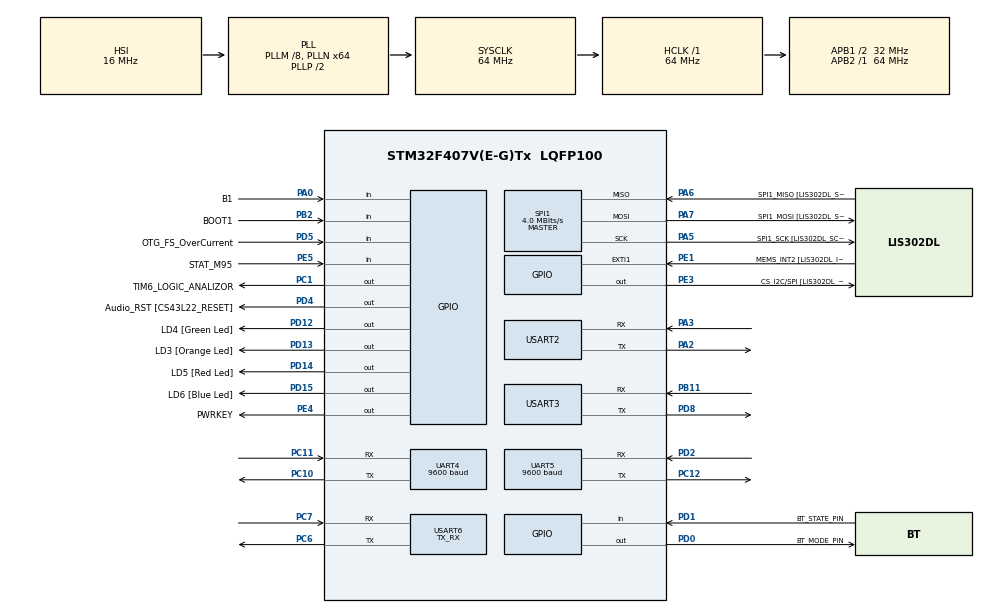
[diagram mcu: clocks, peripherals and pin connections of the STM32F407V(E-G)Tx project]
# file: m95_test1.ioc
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Mcu.Family=STM32F4
Mcu.Name=STM32F407V(E-G)Tx
Mcu.Package=LQFP100
NVIC.PriorityGroup=NVIC_PRIORITYGROUP_4
NVIC.SPI1_IRQn=true\:0\:0\:false\:false\:true\:true\:true\:true
NVIC.TIM6_DAC_IRQn=true\:0\:0\:false\:false\:true\:true\:true\:true
NVIC.UART4_IRQn=true\:0\:0\:false\:false\:true\:true\:true\:true
NVIC.UART5_IRQn=true\:0\:0\:false\:false\:true\:true\:true\:true
NVIC.USART2_IRQn=true\:0\:0\:false\:false\:true\:true\:true\:true
NVIC.USART3_IRQn=true\:0\:0\:false\:false\:true\:true\:true\:true
NVIC.USART6_IRQn=true\:0\:0\:false\:false\:true\:true\:true\:true
PA0-WKUP.GPIO_Label=B1
PA0-WKUP.Signal=GPIO_Input
PA13.Mode=Serial_Wire
PA13.Signal=SYS_JTMS-SWDIO
PA14.Mode=Serial_Wire
PA14.Signal=SYS_JTCK-SWCLK
PA2.GPIO_PuPd=GPIO_PULLUP
PA2.Mode=Asynchronous
PA2.Signal=USART2_TX
PA3.GPIO_PuPd=GPIO_PULLUP
PA3.Mode=Asynchronous
PA3.Signal=USART2_RX
PA5.GPIO_Label=SPI1_SCK [LIS302DL_SCL/SPC]
PA5.GPIO_Mode=GPIO_MODE_AF_PP
PA5.GPIO_PuPd=GPIO_NOPULL
PA5.GPIO_Speed=GPIO_SPEED_FREQ_LOW
PA5.Mode=Full_Duplex_Master
PA5.Signal=SPI1_SCK
PA6.GPIO_Label=SPI1_MISO [LIS302DL_SDO]
PA6.GPIO_Mode=GPIO_MODE_AF_PP
PA6.GPIO_PuPd=GPIO_NOPULL
PA6.GPIO_Speed=GPIO_SPEED_FREQ_LOW
PA6.Mode=Full_Duplex_Master
PA6.Signal=SPI1_MISO
PA7.GPIO_Label=SPI1_MOSI [LIS302DL_SDA/SDI/SDO]
PA7.GPIO_Mode=GPIO_MODE_AF_PP
PA7.GPIO_PuPd=GPIO_NOPULL
PA7.GPIO_Speed=GPIO_SPEED_FREQ_LOW
PA7.Mode=Full_Duplex_Master
PA7.Signal=SPI1_MOSI
PB11.GPIO_PuPd=GPIO_PULLUP
PB11.Mode=Asynchronous
PB11.Signal=USART3_RX
PB2.GPIO_Label=BOOT1
PB2.GPIO_Mode=GPIO_MODE_INPUT
PB2.GPIO_PuPd=GPIO_NOPULL
PB2.Signal=GPIO_Input
PB3.GPIO_Label=SWO
PB3.Signal=SYS_JTDO-SWO
PC1.GPIO_Label=TIM6_LOGIC_ANALIZOR
PC1.Signal=GPIO_Output
PC10.GPIO_PuPd=GPIO_PULLUP
PC10.Mode=Asynchronous
PC10.Signal=UART4_TX
PC11.GPIO_PuPd=GPIO_PULLUP
PC11.Mode=Asynchronous
PC11.Signal=UART4_RX
PC12.GPIO_PuPd=GPIO_PULLUP
PC12.Mode=Asynchronous
PC12.Signal=UART5_TX
PC14-OSC32_IN.GPIO_Label=PC14-OSC32_IN
PC14-OSC32_IN.Signal=RCC_OSC32_IN
PC15-OSC32_OUT.GPIO_Label=PC15-OSC32_OUT
PC15-OSC32_OUT.Signal=RCC_OSC32_OUT
PC6.Mode=Asynchronous
PC6.Signal=USART6_TX
PC7.Mode=Asynchronous
PC7.Signal=USART6_RX
PD0.GPIO_Label=BT_MODE_PIN
PD0.GPIO_PuPd=GPIO_PULLDOWN
PD0.Signal=GPIO_Output
PD1.GPIO_Label=BT_STATE_PIN
PD1.GPIO_PuPd=GPIO_PULLDOWN
PD1.Signal=GPIO_Input
PD12.GPIO_Label=LD4 [Green Led]
PD12.GPIO_PuPd=GPIO_NOPULL
PD12.GPIO_Speed=GPIO_SPEED_FREQ_LOW
PD12.Signal=GPIO_Output
PD13.GPIO_Label=LD3 [Orange Led]
PD13.GPIO_PuPd=GPIO_NOPULL
PD13.GPIO_Speed=GPIO_SPEED_FREQ_LOW
PD13.Signal=GPIO_Output
PD14.GPIO_Label=LD5 [Red Led]
PD14.GPIO_PuPd=GPIO_NOPULL
PD14.GPIO_Speed=GPIO_SPEED_FREQ_LOW
PD14.Signal=GPIO_Output
PD15.GPIO_Label=LD6 [Blue Led]
PD15.GPIO_PuPd=GPIO_NOPULL
PD15.GPIO_Speed=GPIO_SPEED_FREQ_LOW
PD15.Signal=GPIO_Output
PD2.GPIO_PuPd=GPIO_PULLUP
PD2.Mode=Asynchronous
PD2.Signal=UART5_RX
PD4.GPIO_Label=Audio_RST [CS43L22_RESET]
PD4.GPIO_PuPd=GPIO_NOPULL
PD4.GPIO_Speed=GPIO_SPEED_FREQ_LOW
PD4.Signal=GPIO_Output
PD5.GPIO_Label=OTG_FS_OverCurrent
PD5.GPIO_Mode=GPIO_MODE_INPUT
PD5.GPIO_PuPd=GPIO_NOPULL
PD5.Signal=GPIO_Input
PD8.GPIO_ModeDefaultPP=GPIO_MODE_AF_PP
PD8.GPIO_PuPd=GPIO_PULLUP
PD8.Mode=Asynchronous
PD8.Signal=USART3_TX
PE1.GPIO_Label=MEMS_INT2 [LIS302DL_INT2]
PE1.Signal=GPXTI1
PE3.GPIO_Label=CS_I2C/SPI [LIS302DL_CS_I2C/SPI]
PE3.GPIO_PuPd=GPIO_NOPULL
PE3.GPIO_Speed=GPIO_SPEED_FREQ_LOW
PE3.Signal=GPIO_Output
PE4.GPIO_Label=PWRKEY
PE4.Signal=GPIO_Output
PE5.GPIO_Label=STAT_M95
PE5.Signal=GPIO_Input
PH0-OSC_IN.GPIO_Label=PH0-OSC_IN
PH0-OSC_IN.Signal=RCC_OSC_IN
PH1-OSC_OUT.GPIO_Label=PH1-OSC_OUT
PH1-OSC_OUT.Signal=RCC_OSC_OUT
ProjectManager.HeapSize=0x400
ProjectManager.StackSize=0x1200
ProjectManager.TargetToolchain=STM32CubeIDE
RCC.48MHZClocksFreq_Value=18285714.285714287
RCC.AHBFreq_Value=64000000
RCC.APB1CLKDivider=RCC_HCLK_DIV2
RCC.APB1Freq_Value=32000000
RCC.APB1TimFreq_Value=64000000
RCC.APB2Freq_Value=64000000
RCC.APB2TimFreq_Value=64000000
RCC.CortexFreq_Value=64000000
RCC.HCLKFreq_Value=64000000
RCC.HSE_VALUE=8000000
RCC.HSI_VALUE=16000000
RCC.LSE_VALUE=32768
RCC.PLLM=8
RCC.PLLN=64
RCC.PLLQ=7
RCC.SYSCLKFreq_VALUE=64000000
RCC.SYSCLKSource=RCC_SYSCLKSOURCE_PLLCLK
RCC.VCOOutputFreq_Value=128000000
SPI1.BaudRatePrescaler=SPI_BAUDRATEPRESCALER_16
SPI1.CLKPhase=SPI_PHASE_1EDGE
SPI1.CLKPolarity=SPI_POLARITY_LOW
SPI1.CalculateBaudRate=4.0 MBits/s
SPI1.Direction=SPI_DIRECTION_2LINES
SPI1.Mode=SPI_MODE_MASTER
SPI1.VirtualType=VM_MASTER
TIM6.AutoReloadPreload=TIM_AUTORELOAD_PRELOAD_ENABLE
TIM6.Period=3200
TIM6.Prescaler=1
UART4.BaudRate=9600
UART4.VirtualMode=Asynchronous
UART5.BaudRate=9600
UART5.VirtualMode=Asynchronous
USART2.OverSampling=UART_OVERSAMPLING_8
USART2.VirtualMode=VM_ASYNC
USART3.OverSampling=UART_OVERSAMPLING_8
USART3.VirtualMode=VM_ASYNC
USART6.Mode=MODE_TX_RX
USART6.VirtualMode=VM_ASYNC
VP_TIM6_VS_ClockSourceINT.Mode=Enable_Timer
board=STM32F407G-DISC1

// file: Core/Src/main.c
/* USER CODE BEGIN Header */
/**
 ******************************************************************************
 * @file           : main.c
 * @brief          : Main program body
 ******************************************************************************
 * @attention
 *
 * Copyright (c) 2023 STMicroelectronics.
 * All rights reserved.
 *
 * This software is licensed under terms that can be found in the LICENSE file
 * in the root directory of this software component.
 * If no LICENSE file comes with this software, it is provided AS-IS.
 *
 ******************************************************************************
 */
/* USER CODE END Header */
#include "main.h"

/* USER CODE BEGIN Includes */
#include "vehicleTrackingSystem.h"
/* USER CODE END Includes */

SPI_HandleTypeDef hspi1;

TIM_HandleTypeDef htim6;

UART_HandleTypeDef huart4;
UART_HandleTypeDef huart5;
UART_HandleTypeDef huart2;
UART_HandleTypeDef huart3;
UART_HandleTypeDef huart6;

void SystemClock_Config(void);
static void MX_GPIO_Init(void);
static void MX_USART2_UART_Init(void);
static void MX_USART3_UART_Init(void);
static void MX_TIM6_Init(void);
static void MX_USART6_UART_Init(void);
static void MX_UART4_Init(void);
static void MX_UART5_Init(void);
static void MX_SPI1_Init(void);

int main(void)
{

  /* MCU Configuration--------------------------------------------------------*/

  /* Reset of all peripherals, Initializes the Flash interface and the Systick. */
  HAL_Init();

  /* Configure the system clock */
  SystemClock_Config();

  /* Initialize all configured peripherals */
  MX_GPIO_Init();
  MX_USART2_UART_Init();
  MX_USART3_UART_Init();
  MX_TIM6_Init();
  MX_USART6_UART_Init();
  MX_UART4_Init();
  MX_UART5_Init();
  MX_SPI1_Init();
  /* USER CODE BEGIN 2 */

  VTSInit();
  VTSControl();

  /* USER CODE END 2 */

  /* Infinite loop */
	while (1) {

	}
}

void SystemClock_Config(void)
{
  RCC_OscInitTypeDef RCC_OscInitStruct = {0};
  RCC_ClkInitTypeDef RCC_ClkInitStruct = {0};

  /** Configure the main internal regulator output voltage
  */
  __HAL_RCC_PWR_CLK_ENABLE();
  __HAL_PWR_VOLTAGESCALING_CONFIG(PWR_REGULATOR_VOLTAGE_SCALE1);

  /** Initializes the RCC Oscillators according to the specified parameters
  * in the RCC_OscInitTypeDef structure.
  */
  RCC_OscInitStruct.OscillatorType = RCC_OSCILLATORTYPE_HSI;
  RCC_OscInitStruct.HSIState = RCC_HSI_ON;
  RCC_OscInitStruct.HSICalibrationValue = RCC_HSICALIBRATION_DEFAULT;
  RCC_OscInitStruct.PLL.PLLState = RCC_PLL_ON;
  RCC_OscInitStruct.PLL.PLLSource = RCC_PLLSOURCE_HSI;
  RCC_OscInitStruct.PLL.PLLM = 8;
  RCC_OscInitStruct.PLL.PLLN = 64;
  RCC_OscInitStruct.PLL.PLLP = RCC_PLLP_DIV2;
  RCC_OscInitStruct.PLL.PLLQ = 7;
  if (HAL_RCC_OscConfig(&RCC_OscInitStruct) != HAL_OK)
  {
    Error_Handler();
  }

  /** Initializes the CPU, AHB and APB buses clocks
  */
  RCC_ClkInitStruct.ClockType = RCC_CLOCKTYPE_HCLK|RCC_CLOCKTYPE_SYSCLK
                              |RCC_CLOCKTYPE_PCLK1|RCC_CLOCKTYPE_PCLK2;
  RCC_ClkInitStruct.SYSCLKSource = RCC_SYSCLKSOURCE_PLLCLK;
  RCC_ClkInitStruct.AHBCLKDivider = RCC_SYSCLK_DIV1;
  RCC_ClkInitStruct.APB1CLKDivider = RCC_HCLK_DIV2;
  RCC_ClkInitStruct.APB2CLKDivider = RCC_HCLK_DIV1;

  if (HAL_RCC_ClockConfig(&RCC_ClkInitStruct, FLASH_LATENCY_2) != HAL_OK)
  {
    Error_Handler();
  }
}

static void MX_SPI1_Init(void)
{

  /* SPI1 parameter configuration*/
  hspi1.Instance = SPI1;
  hspi1.Init.Mode = SPI_MODE_MASTER;
  hspi1.Init.Direction = SPI_DIRECTION_2LINES;
  hspi1.Init.DataSize = SPI_DATASIZE_8BIT;
  hspi1.Init.CLKPolarity = SPI_POLARITY_LOW;
  hspi1.Init.CLKPhase = SPI_PHASE_1EDGE;
  hspi1.Init.NSS = SPI_NSS_SOFT;
  hspi1.Init.BaudRatePrescaler = SPI_BAUDRATEPRESCALER_16;
  hspi1.Init.FirstBit = SPI_FIRSTBIT_MSB;
  hspi1.Init.TIMode = SPI_TIMODE_DISABLE;
  hspi1.Init.CRCCalculation = SPI_CRCCALCULATION_DISABLE;
  hspi1.Init.CRCPolynomial = 10;
  if (HAL_SPI_Init(&hspi1) != HAL_OK)
  {
    Error_Handler();
  }

}

static void MX_TIM6_Init(void)
{

  TIM_MasterConfigTypeDef sMasterConfig = {0};

  htim6.Instance = TIM6;
  htim6.Init.Prescaler = 1;
  htim6.Init.CounterMode = TIM_COUNTERMODE_UP;
  htim6.Init.Period = 3200;
  htim6.Init.AutoReloadPreload = TIM_AUTORELOAD_PRELOAD_ENABLE;
  if (HAL_TIM_Base_Init(&htim6) != HAL_OK)
  {
    Error_Handler();
  }
  sMasterConfig.MasterOutputTrigger = TIM_TRGO_RESET;
  sMasterConfig.MasterSlaveMode = TIM_MASTERSLAVEMODE_DISABLE;
  if (HAL_TIMEx_MasterConfigSynchronization(&htim6, &sMasterConfig) != HAL_OK)
  {
    Error_Handler();
  }

}

static void MX_UART4_Init(void)
{

  huart4.Instance = UART4;
  huart4.Init.BaudRate = 9600;
  huart4.Init.WordLength = UART_WORDLENGTH_8B;
  huart4.Init.StopBits = UART_STOPBITS_1;
  huart4.Init.Parity = UART_PARITY_NONE;
  huart4.Init.Mode = UART_MODE_TX_RX;
  huart4.Init.HwFlowCtl = UART_HWCONTROL_NONE;
  huart4.Init.OverSampling = UART_OVERSAMPLING_16;
  if (HAL_UART_Init(&huart4) != HAL_OK)
  {
    Error_Handler();
  }

}

static void MX_UART5_Init(void)
{

  huart5.Instance = UART5;
  huart5.Init.BaudRate = 9600;
  huart5.Init.WordLength = UART_WORDLENGTH_8B;
  huart5.Init.StopBits = UART_STOPBITS_1;
  huart5.Init.Parity = UART_PARITY_NONE;
  huart5.Init.Mode = UART_MODE_TX_RX;
  huart5.Init.HwFlowCtl = UART_HWCONTROL_NONE;
  huart5.Init.OverSampling = UART_OVERSAMPLING_16;
  if (HAL_UART_Init(&huart5) != HAL_OK)
  {
    Error_Handler();
  }

}

static void MX_USART2_UART_Init(void)
{

  huart2.Instance = USART2;
  huart2.Init.BaudRate = 115200;
  huart2.Init.WordLength = UART_WORDLENGTH_8B;
  huart2.Init.StopBits = UART_STOPBITS_1;
  huart2.Init.Parity = UART_PARITY_NONE;
  huart2.Init.Mode = UART_MODE_TX_RX;
  huart2.Init.HwFlowCtl = UART_HWCONTROL_NONE;
  huart2.Init.OverSampling = UART_OVERSAMPLING_8;
  if (HAL_UART_Init(&huart2) != HAL_OK)
  {
    Error_Handler();
  }

}

static void MX_USART3_UART_Init(void)
{

  huart3.Instance = USART3;
  huart3.Init.BaudRate = 115200;
  huart3.Init.WordLength = UART_WORDLENGTH_8B;
  huart3.Init.StopBits = UART_STOPBITS_1;
  huart3.Init.Parity = UART_PARITY_NONE;
  huart3.Init.Mode = UART_MODE_TX_RX;
  huart3.Init.HwFlowCtl = UART_HWCONTROL_NONE;
  huart3.Init.OverSampling = UART_OVERSAMPLING_8;
  if (HAL_UART_Init(&huart3) != HAL_OK)
  {
    Error_Handler();
  }

}

static void MX_USART6_UART_Init(void)
{

  huart6.Instance = USART6;
  huart6.Init.BaudRate = 115200;
  huart6.Init.WordLength = UART_WORDLENGTH_8B;
  huart6.Init.StopBits = UART_STOPBITS_1;
  huart6.Init.Parity = UART_PARITY_NONE;
  huart6.Init.Mode = UART_MODE_TX_RX;
  huart6.Init.HwFlowCtl = UART_HWCONTROL_NONE;
  huart6.Init.OverSampling = UART_OVERSAMPLING_16;
  if (HAL_UART_Init(&huart6) != HAL_OK)
  {
    Error_Handler();
  }

}

static void MX_GPIO_Init(void)
{
  GPIO_InitTypeDef GPIO_InitStruct = {0};

  /* GPIO Ports Clock Enable */
  __HAL_RCC_GPIOE_CLK_ENABLE();
  __HAL_RCC_GPIOC_CLK_ENABLE();
  __HAL_RCC_GPIOH_CLK_ENABLE();
  __HAL_RCC_GPIOA_CLK_ENABLE();
  __HAL_RCC_GPIOB_CLK_ENABLE();
  __HAL_RCC_GPIOD_CLK_ENABLE();

  /*Configure GPIO pin Output Level */
  HAL_GPIO_WritePin(GPIOE, CS_I2C_SPI_Pin|PWRKEY_Pin, GPIO_PIN_RESET);

  /*Configure GPIO pin Output Level */
  HAL_GPIO_WritePin(TIM6_LOGIC_ANALIZOR_GPIO_Port, TIM6_LOGIC_ANALIZOR_Pin, GPIO_PIN_RESET);

  /*Configure GPIO pin Output Level */
  HAL_GPIO_WritePin(GPIOD, LD4_Pin|LD3_Pin|LD5_Pin|LD6_Pin
                          |BT_MODE_PIN_Pin|Audio_RST_Pin, GPIO_PIN_RESET);

  /*Configure GPIO pins : PE2 PE6 PE7 PE8
                           PE9 PE10 PE11 PE12
                           PE13 PE14 PE15 PE0 */
  GPIO_InitStruct.Pin = GPIO_PIN_2|GPIO_PIN_6|GPIO_PIN_7|GPIO_PIN_8
                          |GPIO_PIN_9|GPIO_PIN_10|GPIO_PIN_11|GPIO_PIN_12
                          |GPIO_PIN_13|GPIO_PIN_14|GPIO_PIN_15|GPIO_PIN_0;
  GPIO_InitStruct.Mode = GPIO_MODE_ANALOG;
  GPIO_InitStruct.Pull = GPIO_NOPULL;
  HAL_GPIO_Init(GPIOE, &GPIO_InitStruct);

  /*Configure GPIO pins : CS_I2C_SPI_Pin PWRKEY_Pin */
  GPIO_InitStruct.Pin = CS_I2C_SPI_Pin|PWRKEY_Pin;
  GPIO_InitStruct.Mode = GPIO_MODE_OUTPUT_PP;
  GPIO_InitStruct.Pull = GPIO_NOPULL;
  GPIO_InitStruct.Speed = GPIO_SPEED_FREQ_LOW;
  HAL_GPIO_Init(GPIOE, &GPIO_InitStruct);

  /*Configure GPIO pin : STAT_M95_Pin */
  GPIO_InitStruct.Pin = STAT_M95_Pin;
  GPIO_InitStruct.Mode = GPIO_MODE_INPUT;
  GPIO_InitStruct.Pull = GPIO_NOPULL;
  HAL_GPIO_Init(STAT_M95_GPIO_Port, &GPIO_InitStruct);

  /*Configure GPIO pins : PC13 PC0 PC2 PC3
                           PC4 PC5 PC8 PC9 */
  GPIO_InitStruct.Pin = GPIO_PIN_13|GPIO_PIN_0|GPIO_PIN_2|GPIO_PIN_3
                          |GPIO_PIN_4|GPIO_PIN_5|GPIO_PIN_8|GPIO_PIN_9;
  GPIO_InitStruct.Mode = GPIO_MODE_ANALOG;
  GPIO_InitStruct.Pull = GPIO_NOPULL;
  HAL_GPIO_Init(GPIOC, &GPIO_InitStruct);

  /*Configure GPIO pin : TIM6_LOGIC_ANALIZOR_Pin */
  GPIO_InitStruct.Pin = TIM6_LOGIC_ANALIZOR_Pin;
  GPIO_InitStruct.Mode = GPIO_MODE_OUTPUT_PP;
  GPIO_InitStruct.Pull = GPIO_NOPULL;
  GPIO_InitStruct.Speed = GPIO_SPEED_FREQ_LOW;
  HAL_GPIO_Init(TIM6_LOGIC_ANALIZOR_GPIO_Port, &GPIO_InitStruct);

  /*Configure GPIO pin : B1_Pin */
  GPIO_InitStruct.Pin = B1_Pin;
  GPIO_InitStruct.Mode = GPIO_MODE_INPUT;
  GPIO_InitStruct.Pull = GPIO_NOPULL;
  HAL_GPIO_Init(B1_GPIO_Port, &GPIO_InitStruct);

  /*Configure GPIO pins : PA1 PA4 PA8 PA9
                           PA10 PA11 PA12 PA15 */
  GPIO_InitStruct.Pin = GPIO_PIN_1|GPIO_PIN_4|GPIO_PIN_8|GPIO_PIN_9
                          |GPIO_PIN_10|GPIO_PIN_11|GPIO_PIN_12|GPIO_PIN_15;
  GPIO_InitStruct.Mode = GPIO_MODE_ANALOG;
  GPIO_InitStruct.Pull = GPIO_NOPULL;
  HAL_GPIO_Init(GPIOA, &GPIO_InitStruct);

  /*Configure GPIO pins : PB0 PB1 PB10 PB12
                           PB13 PB14 PB15 PB4
                           PB5 PB6 PB7 PB8
                           PB9 */
  GPIO_InitStruct.Pin = GPIO_PIN_0|GPIO_PIN_1|GPIO_PIN_10|GPIO_PIN_12
                          |GPIO_PIN_13|GPIO_PIN_14|GPIO_PIN_15|GPIO_PIN_4
                          |GPIO_PIN_5|GPIO_PIN_6|GPIO_PIN_7|GPIO_PIN_8
                          |GPIO_PIN_9;
  GPIO_InitStruct.Mode = GPIO_MODE_ANALOG;
  GPIO_InitStruct.Pull = GPIO_NOPULL;
  HAL_GPIO_Init(GPIOB, &GPIO_InitStruct);

  /*Configure GPIO pin : BOOT1_Pin */
  GPIO_InitStruct.Pin = BOOT1_Pin;
  GPIO_InitStruct.Mode = GPIO_MODE_INPUT;
  GPIO_InitStruct.Pull = GPIO_NOPULL;
  HAL_GPIO_Init(BOOT1_GPIO_Port, &GPIO_InitStruct);

  /*Configure GPIO pins : PD9 PD10 PD11 PD3
                           PD6 PD7 */
  GPIO_InitStruct.Pin = GPIO_PIN_9|GPIO_PIN_10|GPIO_PIN_11|GPIO_PIN_3
                          |GPIO_PIN_6|GPIO_PIN_7;
  GPIO_InitStruct.Mode = GPIO_MODE_ANALOG;
  GPIO_InitStruct.Pull = GPIO_NOPULL;
  HAL_GPIO_Init(GPIOD, &GPIO_InitStruct);

  /*Configure GPIO pins : LD4_Pin LD3_Pin LD5_Pin LD6_Pin
                           Audio_RST_Pin */
  GPIO_InitStruct.Pin = LD4_Pin|LD3_Pin|LD5_Pin|LD6_Pin
                          |Audio_RST_Pin;
  GPIO_InitStruct.Mode = GPIO_MODE_OUTPUT_PP;
  GPIO_InitStruct.Pull = GPIO_NOPULL;
  GPIO_InitStruct.Speed = GPIO_SPEED_FREQ_LOW;
  HAL_GPIO_Init(GPIOD, &GPIO_InitStruct);

  /*Configure GPIO pin : BT_MODE_PIN_Pin */
  GPIO_InitStruct.Pin = BT_MODE_PIN_Pin;
  GPIO_InitStruct.Mode = GPIO_MODE_OUTPUT_PP;
  GPIO_InitStruct.Pull = GPIO_PULLDOWN;
  GPIO_InitStruct.Speed = GPIO_SPEED_FREQ_LOW;
  HAL_GPIO_Init(BT_MODE_PIN_GPIO_Port, &GPIO_InitStruct);

  /*Configure GPIO pin : BT_STATE_PIN_Pin */
  GPIO_InitStruct.Pin = BT_STATE_PIN_Pin;
  GPIO_InitStruct.Mode = GPIO_MODE_INPUT;
  GPIO_InitStruct.Pull = GPIO_PULLDOWN;
  HAL_GPIO_Init(BT_STATE_PIN_GPIO_Port, &GPIO_InitStruct);

  /*Configure GPIO pin : OTG_FS_OverCurrent_Pin */
  GPIO_InitStruct.Pin = OTG_FS_OverCurrent_Pin;
  GPIO_InitStruct.Mode = GPIO_MODE_INPUT;
  GPIO_InitStruct.Pull = GPIO_NOPULL;
  HAL_GPIO_Init(OTG_FS_OverCurrent_GPIO_Port, &GPIO_InitStruct);

  /*Configure GPIO pin : MEMS_INT2_Pin */
  GPIO_InitStruct.Pin = MEMS_INT2_Pin;
  GPIO_InitStruct.Mode = GPIO_MODE_IT_RISING;
  GPIO_InitStruct.Pull = GPIO_NOPULL;
  HAL_GPIO_Init(MEMS_INT2_GPIO_Port, &GPIO_InitStruct);

}

void Error_Handler(void)
{
  /* USER CODE BEGIN Error_Handler_Debug */
	/* User can add his own implementation to report the HAL error return state */
	__disable_irq();
	while (1) {
		__NVIC_SystemReset();
	}
  /* USER CODE END Error_Handler_Debug */
}
